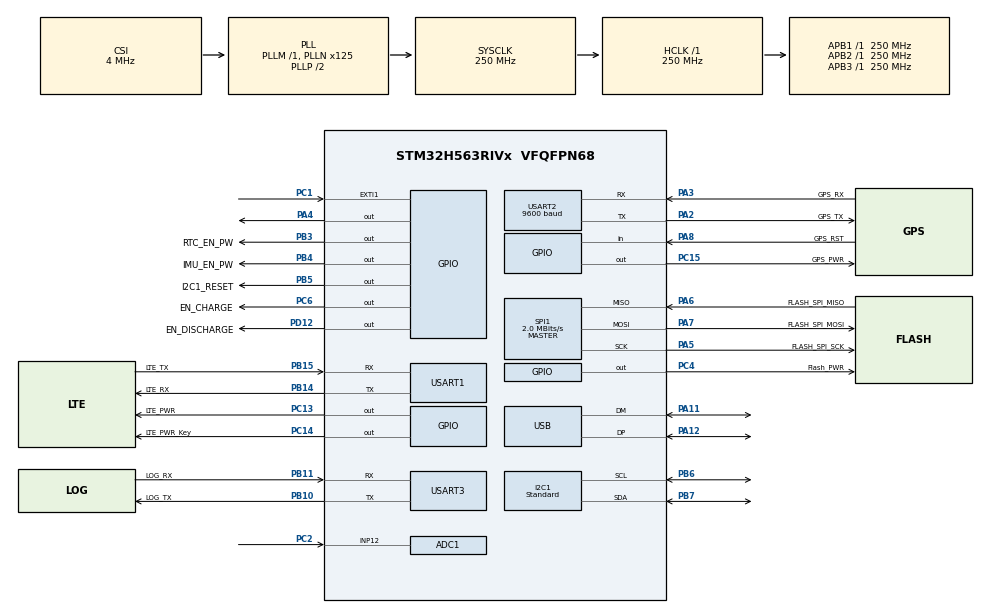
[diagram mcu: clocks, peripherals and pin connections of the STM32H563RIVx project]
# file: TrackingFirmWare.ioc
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ADC1.Channel-3\#ChannelRegularConversion=ADC_CHANNEL_12
ADC1.ContinuousConvMode=ENABLE
ADC1.MonitoredBy-3\#ChannelRegularConversion=__NULL
ADC1.NbrOfConversionFlag=1
ADC1.OffsetNumber-3\#ChannelRegularConversion=ADC_OFFSET_NONE
ADC1.Rank-3\#ChannelRegularConversion=1
ADC1.SamplingTime-3\#ChannelRegularConversion=ADC_SAMPLETIME_640CYCLES_5
ADC1.master=1
BOOTPATH.BootPathName=LEGACY
BOOTPATH.UserSelectedBootPath=LEGACY
CORTEX_M33_NS.userName=CORTEX_M33
I2C1.I2C_Fall_Time=20
I2C1.I2C_Rise_Time=100
I2C1.I2C_Speed_Mode=I2C_Standard
I2C1.Timing=0xA0705983
Mcu.Family=STM32H5
Mcu.Name=STM32H563RIVx
Mcu.Package=VFQFPN68
NVIC.EXTI1_IRQn=true\:0\:0\:true\:false\:true\:true\:true\:true
NVIC.I2C1_ER_IRQn=true\:0\:0\:false\:false\:true\:true\:true\:true
NVIC.I2C1_EV_IRQn=true\:0\:0\:false\:false\:true\:true\:true\:true
NVIC.LPTIM1_IRQn=true\:0\:0\:false\:false\:true\:true\:true\:true
NVIC.PriorityGroup=NVIC_PRIORITYGROUP_4
NVIC.RTC_IRQn=true\:4\:0\:true\:false\:true\:true\:true\:true
NVIC.SPI1_IRQn=true\:0\:0\:false\:false\:true\:true\:true\:true
NVIC.TIM1_BRK_IRQn=true\:0\:0\:false\:false\:true\:true\:true\:true
NVIC.TIM1_CC_IRQn=true\:0\:0\:false\:false\:true\:true\:true\:true
NVIC.TIM1_TRG_COM_IRQn=true\:0\:0\:false\:false\:true\:true\:true\:true
NVIC.TIM1_UP_IRQn=true\:0\:0\:false\:false\:true\:true\:true\:true
NVIC.TIM2_IRQn=true\:0\:0\:false\:false\:true\:true\:true\:true
NVIC.TIM3_IRQn=true\:0\:0\:false\:false\:true\:true\:true\:true
NVIC.USART1_IRQn=true\:2\:0\:true\:false\:true\:true\:true\:true
NVIC.USART2_IRQn=true\:3\:0\:true\:false\:true\:true\:true\:true
NVIC.USART3_IRQn=true\:0\:0\:false\:false\:true\:true\:true\:true
NVIC.USB_DRD_FS_IRQn=true\:4\:0\:true\:false\:false\:true\:true\:true
PA11.Mode=Device
PA11.Signal=USB_DM
PA12.Mode=Device
PA12.Signal=USB_DP
PA13(JTMS/SWDIO).Mode=Serial_Wire
PA13(JTMS/SWDIO).Signal=DEBUG_JTMS-SWDIO
PA14(JTCK/SWCLK).Mode=Serial_Wire
PA14(JTCK/SWCLK).Signal=DEBUG_JTCK-SWCLK
PA2.GPIO_Label=GPS_TX
PA2.Mode=Asynchronous
PA2.Signal=USART2_TX
PA3.GPIO_Label=GPS_RX
PA3.Mode=Asynchronous
PA3.Signal=USART2_RX
PA4.Signal=GPIO_Output
PA5.GPIO_Label=FLASH_SPI_SCK
PA5.Mode=Full_Duplex_Master
PA5.Signal=SPI1_SCK
PA6.GPIO_Label=FLASH_SPI_MISO
PA6.Mode=Full_Duplex_Master
PA6.Signal=SPI1_MISO
PA7.GPIO_Label=FLASH_SPI_MOSI
PA7.Mode=Full_Duplex_Master
PA7.Signal=SPI1_MOSI
PA8.GPIO_Label=GPS_RST
PA8.GPIO_PuPd=GPIO_PULLUP
PA8.Signal=GPIO_Input
PB10.GPIO_Label=LOG_TX
PB10.Mode=Asynchronous
PB10.Signal=USART3_TX
PB11.GPIO_Label=LOG_RX
PB11.Mode=Asynchronous
PB11.Signal=USART3_RX
PB14.GPIO_Label=LTE_RX
PB14.GPIO_Speed=GPIO_SPEED_FREQ_HIGH
PB14.Mode=Asynchronous
PB14.Signal=USART1_TX
PB15.GPIO_Label=LTE_TX
PB15.GPIO_Speed=GPIO_SPEED_FREQ_HIGH
PB15.Mode=Asynchronous
PB15.Signal=USART1_RX
PB3(JTDO/TRACESWO).GPIO_Label=RTC_EN_PW
PB3(JTDO/TRACESWO).Signal=GPIO_Output
PB4(NJTRST).GPIO_Label=IMU_EN_PW
PB4(NJTRST).Signal=GPIO_Output
PB5.GPIO_Label=I2C1_RESET
PB5.Signal=GPIO_Output
PB6.Mode=I2C
PB6.Signal=I2C1_SCL
PB7.Mode=I2C
PB7.Signal=I2C1_SDA
PC1.GPIO_ModeDefaultEXTI=GPIO_MODE_IT_RISING_FALLING
PC1.GPIO_PuPd=GPIO_NOPULL
PC1.Signal=GPXTI1
PC13.GPIO_Label=LTE_PWR
PC13.Signal=GPIO_Output
PC14-OSC32_IN(OSC32_IN).GPIO_Label=LTE_PWR_Key
PC14-OSC32_IN(OSC32_IN).Signal=GPIO_Output
PC15-OSC32_OUT(OSC32_OUT).GPIO_Label=GPS_PWR
PC15-OSC32_OUT(OSC32_OUT).Signal=GPIO_Output
PC2.Signal=ADCx_INP12
PC4.GPIO_Label=Flash_PWR
PC4.Signal=GPIO_Output
PC6.GPIO_Label=EN_CHARGE
PC6.Signal=GPIO_Output
PD12.GPIO_Label=EN_DISCHARGE
PD12.Signal=GPIO_Output
PH0-OSC_IN(PH0).Mode=HSE-External-Oscillator
PH0-OSC_IN(PH0).Signal=RCC_OSC_IN
PH1-OSC_OUT(PH1).Mode=HSE-External-Oscillator
PH1-OSC_OUT(PH1).Signal=RCC_OSC_OUT
ProjectManager.HeapSize=0x1000
ProjectManager.StackSize=0x1000
ProjectManager.TargetToolchain=Makefile
RCC.ADCFreq_Value=250000000
RCC.AHBFreq_Value=250000000
RCC.APB1Freq_Value=250000000
RCC.APB1TimFreq_Value=250000000
RCC.APB2Freq_Value=250000000
RCC.APB2TimFreq_Value=250000000
RCC.APB3Freq_Value=250000000
RCC.CSI_VALUE=4000000
RCC.CortexFreq_Value=250000000
RCC.EPOD_VALUE=4000000
RCC.HCLKFreq_Value=250000000
RCC.HSE_VALUE=8000000
RCC.HSI48_VALUE=48000000
RCC.HSI_VALUE=64000000
RCC.LSE_VALUE=32768
RCC.LSIRC_VALUE=32000
RCC.PLL2FRACN=0
RCC.PLL2N=125
RCC.PLL2P=4
RCC.PLL2Q=4
RCC.PLL2Source=RCC_PLL2_SOURCE_HSI
RCC.PLL3FRACN=0
RCC.PLL3N=75
RCC.PLL3P=4
RCC.PLL3Q=4
RCC.PLL3Source=RCC_PLL3_SOURCE_HSI
RCC.PLLFRACN=0
RCC.PLLN=125
RCC.SPI1CLockSelection=RCC_SPI1CLKSOURCE_CLKP
RCC.SYSCLKFreq_VALUE=250000000
RCC.SYSCLKSource=RCC_SYSCLKSOURCE_PLLCLK
RCC.USBFreq_Value=48000000
RCC.VCOOutputFreq_Value=500000000
RTC.SynchPrediv=249
RTC.WakeUpClock-WakeUp=RTC_WAKEUPCLOCK_CK_SPRE_16BITS
RTC.WakeUpCounter-WakeUp=1
SH.ADCx_INP12.0=ADC1_INP12,IN12-Single-Ended
SPI1.BaudRatePrescaler=SPI_BAUDRATEPRESCALER_16
SPI1.CalculateBaudRate=2.0 MBits/s
SPI1.DataSize=SPI_DATASIZE_8BIT
SPI1.Direction=SPI_DIRECTION_2LINES
SPI1.Mode=SPI_MODE_MASTER
SPI1.VirtualType=VM_MASTER
USART1.DMADisableonRxErrorParam=ADVFEATURE_DMA_ENABLEONRXERROR
USART1.OverrunDisableParam=ADVFEATURE_OVERRUN_ENABLE
USART1.SwapParam=ADVFEATURE_SWAP_ENABLE
USART1.VirtualMode-Asynchronous=VM_ASYNC
USART2.BaudRate=9600
USART2.SwapParam=ADVFEATURE_SWAP_DISABLE
USART2.VirtualMode-Asynchronous=VM_ASYNC
USART3.VirtualMode-Asynchronous=VM_ASYNC
USB.VirtualMode=Device_Only
VP_BOOTPATH_VS_BOOTPATH.Mode=BP_Activate
VP_CORTEX_M33_NS_VS_Hclk.Mode=Hclk_Mode
VP_ICACHE_VS_ENABLE_ICACHE_MEMORY.Mode=Memoryregions
VP_LPTIM1_VS_LPTIM_counterModeInternalClock.Mode=Counts__internal_clock_event_00
VP_MEMORYMAP_VS_MEMORYMAP.Mode=CurAppReg
VP_PWR_VS_LPOM.Mode=PowerOptimisation
VP_PWR_VS_SECSignals.Mode=Security/Privilege
VP_RTC_VS_RTC_Activate.Mode=RTC_Enabled
VP_RTC_VS_RTC_Calendar.Mode=RTC_Calendar
VP_RTC_VS_RTC_WakeUp_intern.Mode=WakeUp
VP_TIM1_VS_ClockSourceINT.Mode=Internal
VP_TIM2_VS_ClockSourceINT.Mode=Internal
VP_TIM3_VS_ClockSourceINT.Mode=Internal
board=custom

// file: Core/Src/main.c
/* USER CODE BEGIN Header */
/**
  ******************************************************************************
  * @file           : main.c
  * @brief          : Main program body
  ******************************************************************************
  * @attention
  *
  * Copyright (c) 2026 STMicroelectronics.
  * All rights reserved.
  *
  * This software is licensed under terms that can be found in the LICENSE file
  * in the root directory of this software component.
  * If no LICENSE file comes with this software, it is provided AS-IS.
  *
  ******************************************************************************
  */
/* USER CODE END Header */
#include "main.h"
#include "adc.h"
#include "i2c.h"
#include "icache.h"
#include "lptim.h"
#include "rtc.h"
#include "spi.h"
#include "tim.h"
#include "usart.h"
#include "usb.h"
#include "gpio.h"

/* USER CODE BEGIN Includes */
#include "app.h"
#include "sx_board.h"
/* USER CODE END Includes */

void SystemClock_Config(void);
void PeriphCommonClock_Config(void);

/* USER CODE BEGIN 0 */
static const char *TAG = "MAIN";

/* USER CODE END 0 */

int main(void)
{

  /* USER CODE BEGIN 1 */
  __enable_irq();
  SCB->SHCSR |= SCB_SHCSR_BUSFAULTENA_Msk;
  /* USER CODE END 1 */

  /* MCU Configuration--------------------------------------------------------*/

  /* Reset of all peripherals, Initializes the Flash interface and the Systick. */
  HAL_Init();

  /* Configure the system clock */
  SystemClock_Config();

  /* Configure the peripherals common clocks */
  PeriphCommonClock_Config();

  /* Initialize all configured peripherals */
  MX_GPIO_Init();
  MX_I2C1_Init();
  MX_SPI1_Init();
  MX_USART1_UART_Init();
  MX_USART2_UART_Init();
  MX_USART3_UART_Init();
  MX_USB_PCD_Init();
  MX_ICACHE_Init();
  MX_LPTIM1_Init();
  MX_RTC_Init();
  MX_TIM1_Init();
  MX_TIM3_Init();
  MX_ADC1_Init();
  MX_TIM2_Init();
  /* USER CODE BEGIN 2 */
  uint32_t last_tick = 0;
  HAL_RTCEx_DeactivateWakeUpTimer(&hrtc);
  sx_board_init();
  app_init();
  /* USER CODE END 2 */

  /* Infinite loop */
  while (1)
  {

    /* USER CODE BEGIN 3 */
    uint32_t now = HAL_GetTick();
    uint32_t delta = now - last_tick;

    if (delta > 0)
    {
        last_tick = now;
        app_process(delta);
    }

  }
  /* USER CODE END 3 */
}

void SystemClock_Config(void)
{
  RCC_OscInitTypeDef RCC_OscInitStruct = {0};
  RCC_ClkInitTypeDef RCC_ClkInitStruct = {0};

  /** Configure the main internal regulator output voltage
  */
  __HAL_PWR_VOLTAGESCALING_CONFIG(PWR_REGULATOR_VOLTAGE_SCALE0);

  while(!__HAL_PWR_GET_FLAG(PWR_FLAG_VOSRDY)) {}

  /** Initializes the RCC Oscillators according to the specified parameters
  * in the RCC_OscInitTypeDef structure.
  */
  RCC_OscInitStruct.OscillatorType = RCC_OSCILLATORTYPE_HSI48|RCC_OSCILLATORTYPE_LSI
                              |RCC_OSCILLATORTYPE_CSI;
  RCC_OscInitStruct.LSIState = RCC_LSI_ON;
  RCC_OscInitStruct.HSI48State = RCC_HSI48_ON;
  RCC_OscInitStruct.CSIState = RCC_CSI_ON;
  RCC_OscInitStruct.CSICalibrationValue = RCC_CSICALIBRATION_DEFAULT;
  RCC_OscInitStruct.PLL.PLLState = RCC_PLL_ON;
  RCC_OscInitStruct.PLL.PLLSource = RCC_PLL1_SOURCE_CSI;
  RCC_OscInitStruct.PLL.PLLM = 1;
  RCC_OscInitStruct.PLL.PLLN = 125;
  RCC_OscInitStruct.PLL.PLLP = 2;
  RCC_OscInitStruct.PLL.PLLQ = 2;
  RCC_OscInitStruct.PLL.PLLR = 2;
  RCC_OscInitStruct.PLL.PLLRGE = RCC_PLL1_VCIRANGE_2;
  RCC_OscInitStruct.PLL.PLLVCOSEL = RCC_PLL1_VCORANGE_WIDE;
  RCC_OscInitStruct.PLL.PLLFRACN = 0;
  if (HAL_RCC_OscConfig(&RCC_OscInitStruct) != HAL_OK)
  {
    Error_Handler();
  }

  /** Initializes the CPU, AHB and APB buses clocks
  */
  RCC_ClkInitStruct.ClockType = RCC_CLOCKTYPE_HCLK|RCC_CLOCKTYPE_SYSCLK
                              |RCC_CLOCKTYPE_PCLK1|RCC_CLOCKTYPE_PCLK2
                              |RCC_CLOCKTYPE_PCLK3;
  RCC_ClkInitStruct.SYSCLKSource = RCC_SYSCLKSOURCE_PLLCLK;
  RCC_ClkInitStruct.AHBCLKDivider = RCC_SYSCLK_DIV1;
  RCC_ClkInitStruct.APB1CLKDivider = RCC_HCLK_DIV1;
  RCC_ClkInitStruct.APB2CLKDivider = RCC_HCLK_DIV1;
  RCC_ClkInitStruct.APB3CLKDivider = RCC_HCLK_DIV1;

  if (HAL_RCC_ClockConfig(&RCC_ClkInitStruct, FLASH_LATENCY_5) != HAL_OK)
  {
    Error_Handler();
  }

  /** Configure the programming delay
  */
  __HAL_FLASH_SET_PROGRAM_DELAY(FLASH_PROGRAMMING_DELAY_2);
}

void PeriphCommonClock_Config(void)
{
  RCC_PeriphCLKInitTypeDef PeriphClkInitStruct = {0};

  /** Initializes the peripherals clock
  */
  PeriphClkInitStruct.PeriphClockSelection = RCC_PERIPHCLK_CKPER;
  PeriphClkInitStruct.CkperClockSelection = RCC_CLKPSOURCE_HSI;
  if (HAL_RCCEx_PeriphCLKConfig(&PeriphClkInitStruct) != HAL_OK)
  {
    Error_Handler();
  }
}

void Error_Handler(void)
{
  __disable_irq();
  while (1)
  {
  }
}
